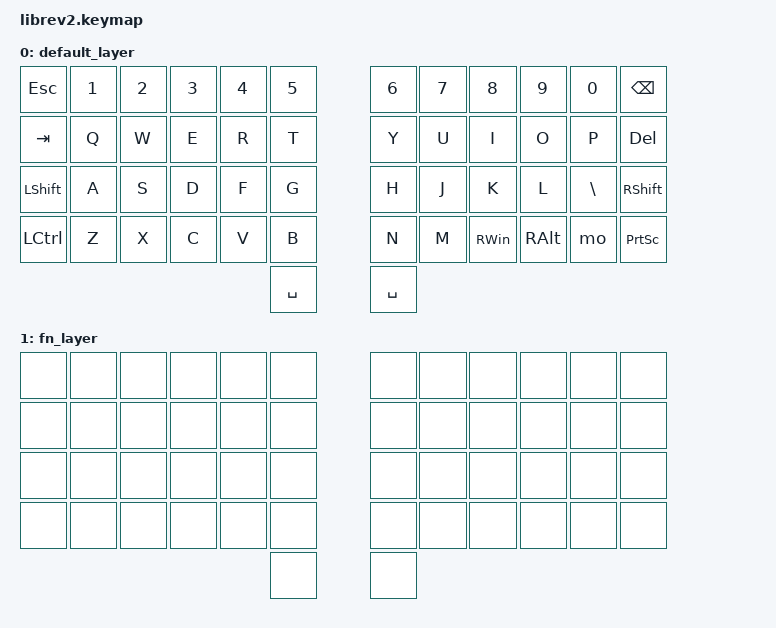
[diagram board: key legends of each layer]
#include <behaviors.dtsi>
#include <dt-bindings/zmk/keys.h>

/ {
    keymap {
      compatible = "zmk,keymap";
                default_layer {
// ---------------------------------------------------------------------------------
// |  ESC |  1  |  2  |  3  |  4  |  5  |           |  6  |  7  |  8  |  9  |  0  | BKSP |
// |  TAB |  Q  |  W  |  E  |  R  |  T  |           |  Y  |  U  |  I  |  O  |  P  |  DEL |
// | SHFT |  A  |  S  |  D  |  F  |  G  |           |  H  |  J  |  K  |  L  |  \  | SHFT |
// | CRTL |  Z  |  X  |  C  |  V  |  B  |           |  N  |  M  | Win | Alt | Fn  |PrtSc |
// |      |     |     |     |     |     | SPC | Ent |     |     |     |     |     |      |
                        bindings = <
   &kp ESC    &kp N1    &kp N2    &kp N3     &kp N4     &kp N5               &kp N6     &kp N7  &kp N8     &kp N9    &kp N0    &kp BSPC
   &kp TAB    &kp Q     &kp W     &kp E      &kp R      &kp T                &kp Y      &kp U   &kp I      &kp O     &kp P     &kp DELETE
   &kp LSHFT  &kp A     &kp S     &kp D      &kp F      &kp G                &kp H      &kp J   &kp K      &kp L     &kp BACKSLASH  &kp RIGHT_SHIFT
   &kp LCTRL  &kp Z     &kp X     &kp C      &kp V      &kp B                &kp N      &kp M   &kp RIGHT_WIN  &kp RIGHT_ALT   &mo  &kp PRINTSCREEN
   &kp SPACE                                                                 &kp SPACE 
                        >;
                };
            fn_layer {
// ---------------------------------------------------------------------------------
// |  ESC |  1  |  2  |  3  |  4  |  5  |           |  6  |  7  |  8  |  9  |  0  | BKSP |
// |  TAB |  Q  |  W  |  E  |  R  |  T  |           |  Y  |  U  |  I  |  O  |  P  |  DEL |
// | SHFT |  A  |  S  |  D  |  F  |  G  |           |  H  |  J  |  K  |  L  |  \  | SHFT |
// | CRTL |  Z  |  X  |  C  |  V  |  B  |           |  N  |  M  | Win | Alt | Fn  |PrtSc |
// |      |     |     |     |     |     | SPC | Ent |     |     |     |     |     |      |
                        bindings = <
   &none    &none    &none    &none    &none    &none                        &none    &none    &none    &none    &none    &none       
   &none    &none    &none    &none    &none    &none                        &none    &none    &none    &none    &none    &none  
   &none    &none    &none    &none    &none    &none                        &none    &none    &none    &none    &none    &none  
   &none    &none    &none    &none    &none    &none                        &none    &none    &none    &none    &none    &none  
   &none                                                                &none 
                        >;
                };

        };
}; 
